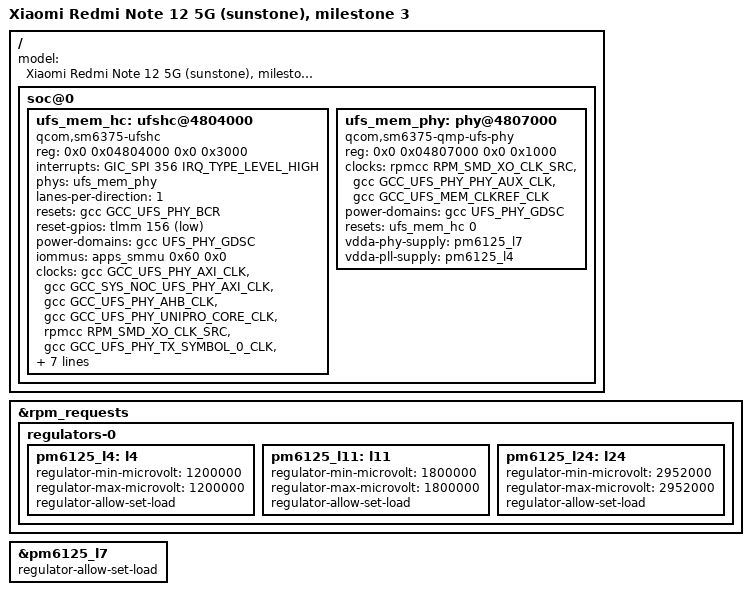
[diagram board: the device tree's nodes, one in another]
// SPDX-License-Identifier: BSD-3-Clause
/*
 * Xiaomi Redmi Note 12 5G (sunstone), SM4375 "blair": milestone 3 tree = M2 + UFS.
 *
 * sm6375.dtsi has no UFS nodes. These follow the downstream blair DT: ufshc@4804000 with one
 * lane, and a QMP v4 PHY that downstream drives as "qcom,ufs-phy-qmp-v4-yupik" (SC7280 tables,
 * kernel/patches/0001 adds the one-lane sm6375 entry). Inline crypto (ICE) is left out for now.
 * Supplies: vcc pm6125_l24 (2.95 V), vccq2 pm6125_l11 (1.8 V), PHY pm6125_l7 / pm6125_l4,
 * vdd-hba = the UFS_PHY GDSC. No interconnect driver for sm6375 yet: bus votes stay as ABL left them.
 */
#include <dt-bindings/gpio/gpio.h>
#include "sm4375-xiaomi-sunstone-m2.dts"

/ {
	model = "Xiaomi Redmi Note 12 5G (sunstone), milestone 3";

	soc@0 {
		ufs_mem_hc: ufshc@4804000 {
			compatible = "qcom,sm6375-ufshc", "qcom,ufshc", "jedec,ufs-2.0";
			reg = <0x0 0x04804000 0x0 0x3000>;
			reg-names = "std";
			interrupts = <GIC_SPI 356 IRQ_TYPE_LEVEL_HIGH>;
			phys = <&ufs_mem_phy>;
			phy-names = "ufsphy";
			lanes-per-direction = <1>;
			#reset-cells = <1>;
			resets = <&gcc GCC_UFS_PHY_BCR>;
			reset-names = "rst";
			reset-gpios = <&tlmm 156 GPIO_ACTIVE_LOW>;

			power-domains = <&gcc UFS_PHY_GDSC>;
			iommus = <&apps_smmu 0x60 0x0>;

			clocks = <&gcc GCC_UFS_PHY_AXI_CLK>,
				 <&gcc GCC_SYS_NOC_UFS_PHY_AXI_CLK>,
				 <&gcc GCC_UFS_PHY_AHB_CLK>,
				 <&gcc GCC_UFS_PHY_UNIPRO_CORE_CLK>,
				 <&rpmcc RPM_SMD_XO_CLK_SRC>,
				 <&gcc GCC_UFS_PHY_TX_SYMBOL_0_CLK>,
				 <&gcc GCC_UFS_PHY_RX_SYMBOL_0_CLK>;
			clock-names = "core_clk",
				      "bus_aggr_clk",
				      "iface_clk",
				      "core_clk_unipro",
				      "ref_clk",
				      "tx_lane0_sync_clk",
				      "rx_lane0_sync_clk";
			freq-table-hz = <50000000 200000000>,
					<0 0>,
					<0 0>,
					<37500000 150000000>,
					<0 0>,
					<0 0>,
					<0 0>;

			vcc-supply = <&pm6125_l24>;
			vcc-max-microamp = <800000>;
			vccq2-supply = <&pm6125_l11>;
			vccq2-max-microamp = <800000>;
		};

		ufs_mem_phy: phy@4807000 {
			compatible = "qcom,sm6375-qmp-ufs-phy";
			reg = <0x0 0x04807000 0x0 0x1000>;

			clocks = <&rpmcc RPM_SMD_XO_CLK_SRC>,
				 <&gcc GCC_UFS_PHY_PHY_AUX_CLK>,
				 <&gcc GCC_UFS_MEM_CLKREF_CLK>;
			clock-names = "ref",
				      "ref_aux",
				      "qref";

			power-domains = <&gcc UFS_PHY_GDSC>;

			resets = <&ufs_mem_hc 0>;
			reset-names = "ufsphy";

			vdda-phy-supply = <&pm6125_l7>;
			vdda-pll-supply = <&pm6125_l4>;

			#phy-cells = <0>;
		};
	};
};

&rpm_requests {
	regulators-0 {
		/* UFS PHY PLL (downstream 1.1-1.3 V) */
		pm6125_l4: l4 {
			regulator-min-microvolt = <1200000>;
			regulator-max-microvolt = <1200000>;
			regulator-allow-set-load;
		};

		/* UFS vccq2 */
		pm6125_l11: l11 {
			regulator-min-microvolt = <1800000>;
			regulator-max-microvolt = <1800000>;
			regulator-allow-set-load;
		};

		/* UFS vcc (downstream vcc-voltage-level 2.95-2.96 V) */
		pm6125_l24: l24 {
			regulator-min-microvolt = <2952000>;
			regulator-max-microvolt = <2952000>;
			regulator-allow-set-load;
		};
	};
};

&pm6125_l7 {
	regulator-allow-set-load;
};
